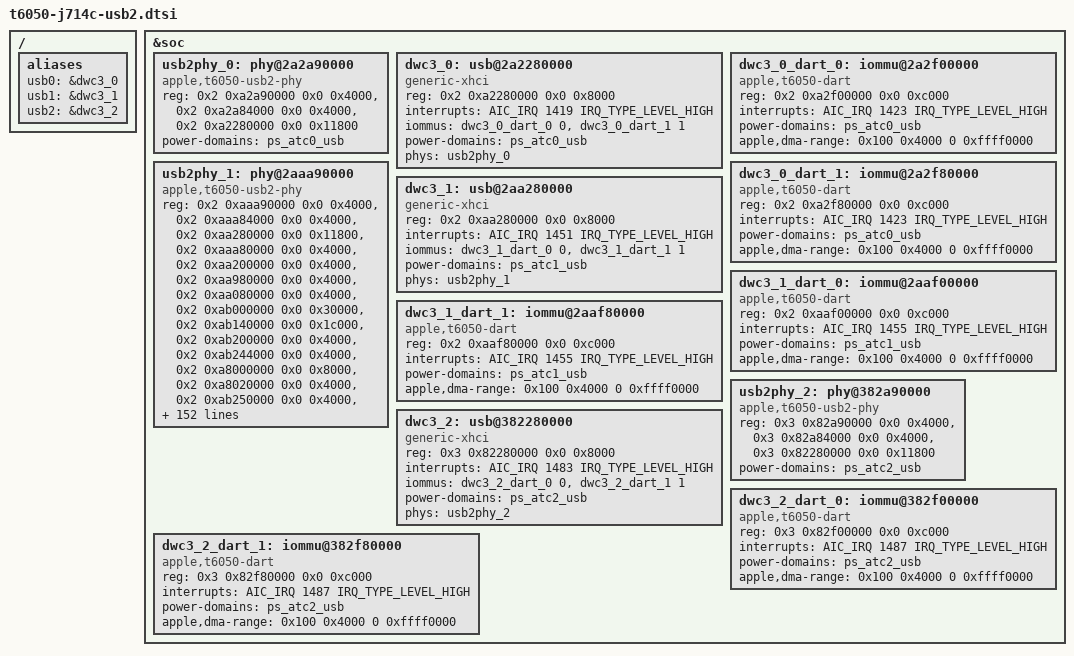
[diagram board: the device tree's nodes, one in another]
// SPDX-License-Identifier: GPL-2.0+ OR MIT
/*
 * USB 2.0 host on USB-C ports 0, 1 and 2 of the MacBook Pro 14" (M5 Max, J714c).
 *
 * The full T6050 Type-C PHY has no Linux driver yet (see t6050-j714c-usb.dtsi).
 * Each port's apple,t6050-usb2-phy puts its usb2phy, pipe handler and dwc3
 * core into USB 2.0 host mode (the loader's usb_t6050_host_prep sequence),
 * and the generic xHCI platform driver drives the xHCI registers after
 * phy_init(). PHY windows: atc-phyN reg 0 (usb2phy) and usb-drdN reg 3
 * (pipe handler). Addresses from
 * the ADT: usb-drd0 0x2a2280000, dart-usb0 0x2a2f00000/0x2a2f80000,
 * usb-drd1 0x2aa280000, dart-usb1 0x2aaf00000/0x2aaf80000,
 * usb-drd2 0x382280000, dart-usb2 0x382f00000/0x382f80000.
 * Port 1 is the proxy cable.
 */

/ {
	aliases {
		usb0 = &dwc3_0;
		usb1 = &dwc3_1;
		usb2 = &dwc3_2;
	};
};

&soc {
	usb2phy_0: phy@2a2a90000 {
		compatible = "apple,t6050-usb2-phy";
		reg = <0x2 0xa2a90000 0x0 0x4000>, <0x2 0xa2a84000 0x0 0x4000>,
		      <0x2 0xa2280000 0x0 0x11800>;
		reg-names = "usb2phy", "pipehandler", "core";
		#phy-cells = <0>;
		power-domains = <&ps_atc0_usb>;
	};

	dwc3_0: usb@2a2280000 {
		compatible = "generic-xhci";
		reg = <0x2 0xa2280000 0x0 0x8000>;
		interrupts = <AIC_IRQ 1419 IRQ_TYPE_LEVEL_HIGH>;
		iommus = <&dwc3_0_dart_0 0>, <&dwc3_0_dart_1 1>;
		power-domains = <&ps_atc0_usb>;
		phys = <&usb2phy_0>;
		phy-names = "usb2-phy";
	};

	dwc3_0_dart_0: iommu@2a2f00000 {
		compatible = "apple,t6050-dart", "apple,t8110-dart";
		reg = <0x2 0xa2f00000 0x0 0xc000>;
		interrupts = <AIC_IRQ 1423 IRQ_TYPE_LEVEL_HIGH>;
		power-domains = <&ps_atc0_usb>;
		#iommu-cells = <1>;
		apple,dma-range = <0x100 0x4000 0 0xffff0000>;
	};

	dwc3_0_dart_1: iommu@2a2f80000 {
		compatible = "apple,t6050-dart", "apple,t8110-dart";
		reg = <0x2 0xa2f80000 0x0 0xc000>;
		interrupts = <AIC_IRQ 1423 IRQ_TYPE_LEVEL_HIGH>;
		power-domains = <&ps_atc0_usb>;
		#iommu-cells = <1>;
		apple,dma-range = <0x100 0x4000 0 0xffff0000>;
	};

	/*
	 * Port 1 also gets SuperSpeed: the Type-C PHY windows (atc-phy1 reg 2,
	 * 38, 39, 40, 41, 42, 43; usb-drd1 reg 1, 5, 6, 8), the PMGR power
	 * states of the CIO domains and of the PHY CPU, and the ADT tunables,
	 * offsets relative to the window of the same name.
	 */
	usb2phy_1: phy@2aaa90000 {
		compatible = "apple,t6050-usb2-phy";
		reg = <0x2 0xaaa90000 0x0 0x4000>, <0x2 0xaaa84000 0x0 0x4000>,
		      <0x2 0xaa280000 0x0 0x11800>, <0x2 0xaaa80000 0x0 0x4000>,
		      <0x2 0xaa200000 0x0 0x4000>, <0x2 0xaa980000 0x0 0x4000>,
		      <0x2 0xaa080000 0x0 0x4000>, <0x2 0xab000000 0x0 0x30000>,
		      <0x2 0xab140000 0x0 0x1c000>, <0x2 0xab200000 0x0 0x4000>,
		      <0x2 0xab244000 0x0 0x4000>, <0x2 0xa8000000 0x0 0x8000>,
		      <0x2 0xa8020000 0x0 0x4000>, <0x2 0xab250000 0x0 0x4000>,
		      <0x2 0x80600000 0x0 0x1000>, <0x2 0x88300000 0x0 0x1000>;
		reg-names = "usb2phy", "pipehandler", "core", "pctl",
			    "drd-cfg", "ausbc-debug", "bulk-fabric", "atc",
			    "atc-mxwrap", "atc-power", "atc-fabric", "atc-axi2af",
			    "atc-axi2af-lioa", "atc-common-cfg", "pmgr", "pmgr-mxwrap";
		#phy-cells = <0>;
		power-domains = <&ps_atc1_usb>;

		apple,tunable-gbl =
			<0xc100 0x8 0x8>,
			<0xc164 0x2 0x0>,
			<0xc104 0x1ef00 0x2f00>,
			<0xc11c 0x100 0x0>,
			<0xc12c 0xa07ff 0x800c8>,
			<0xc200 0x2000100 0x2000100>,
			<0xc604 0x1000 0x0>,
			<0xc628 0xff0000ff 0x6000006>,
			<0xc62c 0xff0000ff 0x8000008>,
			<0xc680 0xffffffff 0x6f000006>,
			<0xc684 0xffffffff 0x60000>;
		apple,tunable-cfg =
			<0x20 0xff 0x1b>;
		apple,tunable-link =
			<0xd010 0xff000000 0xff000000>,
			<0xd020 0x7ff00000 0x4e900000>,
			<0xd024 0x1f8000 0xb8000>,
			<0xd060 0x3ffff 0x600>;
		apple,tunable-ausbc-debug =
			<0xc 0x1f 0x0>;
		apple,tunable-bulk-fabric =
			<0x8 0x8000 0x0>,
			<0x14 0x8000 0x0>,
			<0x20 0x8000 0x0>;
		apple,tunable-pipehandler =
			<0x44 0x4 0x4>;
		apple,tunable-cio =
			<0xcd20 0xff0000 0x1e0000>;
		apple,tunable-atc-common-cfg =
			<0x8 0x1 0x1>;
		apple,tunable-atc-fabric =
			<0x4 0x3f003f 0x200020>,
			<0xc 0xf1 0xa1>,
			<0x10 0x801f 0x4>,
			<0x18 0x3f003f 0x200020>,
			<0x20 0xf1 0xa1>,
			<0x24 0x801f 0x4>,
			<0x2c 0xff00ff 0x960096>,
			<0x34 0xf1 0x71>,
			<0x38 0x801f 0x4>,
			<0x40 0x3f 0x20>,
			<0x48 0x801f 0x4>,
			<0x50 0x7f007f 0x450045>,
			<0x58 0x801f 0x4>,
			<0x60 0x3f 0x20>,
			<0x68 0x801f 0x4>,
			<0x70 0x1 0x1>,
			<0x74 0x801f 0x4>,
			<0x7c 0x7f007f 0x400040>,
			<0x80 0xf1 0x11>,
			<0x84 0x1 0x1>,
			<0x88 0x1 0x1>,
			<0x8c 0x801f 0x4>,
			<0x94 0x3f003f 0x240024>,
			<0x98 0xf1 0x11>,
			<0x9c 0x801f 0x4>,
			<0xa4 0x1ff 0x1e0>,
			<0xa8 0x801f 0x4>,
			<0xb0 0x3f 0x20>,
			<0xb8 0x801f 0x4>,
			<0xc0 0x3f 0x20>,
			<0xc8 0x801f 0x4>,
			<0xd0 0x1f001f 0x100010>,
			<0xd8 0x1 0x1>,
			<0xdc 0x1 0x1>,
			<0xe0 0x801f 0x4>,
			<0xe8 0xf 0x8>,
			<0xec 0x801f 0x4>,
			<0xf4 0xffffffff 0x1010101>,
			<0xf8 0x801f 0x4>,
			<0x100 0x1 0x1>,
			<0x104 0x1 0x1>,
			<0x108 0x801f 0x4>,
			<0x110 0x801f 0x4>,
			<0x118 0x801f 0x4>,
			<0x120 0x1 0x1>,
			<0x124 0x1 0x1>,
			<0x128 0x801f 0x4>,
			<0x130 0xffffffff 0x1010101>,
			<0x134 0x801f 0x4>,
			<0x13c 0x1 0x1>,
			<0x140 0x1 0x1>,
			<0x144 0x801f 0x4>,
			<0x14c 0x1 0x1>,
			<0x150 0x1 0x1>,
			<0x154 0x801f 0x4>,
			<0x15c 0x801f 0x4>,
			<0x164 0xffffffff 0x1010101>,
			<0x168 0xffff 0x101>,
			<0x16c 0x801f 0x4>,
			<0x174 0x1 0x1>,
			<0x178 0x1 0x1>,
			<0x17c 0x801f 0x4>,
			<0x184 0x1 0x1>,
			<0x188 0x1 0x1>,
			<0x18c 0x801f 0x4>;
		apple,tunable-atc-axi2af =
			<0x0 0x800000ff 0x80000023>,
			<0x4 0x80ff00ff 0x80220002>,
			<0x8 0x80ff00ff 0x80220002>,
			<0xc 0x80ff00ff 0x80220006>,
			<0x10 0x80ff00ff 0x80220002>,
			<0x14 0x80ff00ff 0x80200004>,
			<0x18 0x80ff00ff 0x80220002>,
			<0x1c 0x80ff00ff 0x80220002>,
			<0x20 0x80ff00ff 0x80220002>,
			<0x24 0x800000ff 0x8000001a>,
			<0x28 0x800000ff 0x80000046>,
			<0x2c 0x80ff00ff 0x80460004>,
			<0x30 0x80ff00ff 0x80460004>,
			<0x34 0x80ff00ff 0x80420008>,
			<0x38 0x80ff00ff 0x80460004>,
			<0x3c 0x80ff00ff 0x80460004>,
			<0x40 0x800000ff 0x8000001a>,
			<0x44 0x800000ff 0x8000001a>,
			<0x48 0x800000ff 0x8000001d>,
			<0x100 0xff 0xff>,
			<0x104 0x3 0x3>,
			<0x300 0x3 0x1>,
			<0x304 0x3f3f0000 0x4040000>,
			<0x308 0x3ff 0xd>,
			<0x30c 0x700003ff 0xc>,
			<0x310 0x80001f 0x800001>,
			<0x314 0x8080001f 0x80800001>,
			<0x318 0x80001f 0x800001>,
			<0x31c 0x8080001f 0x80800001>,
			<0x320 0x80001f 0x800003>,
			<0x324 0x8080001f 0x80800003>,
			<0x328 0x80001f 0x800003>,
			<0x32c 0x8080001f 0x80800003>,
			<0x330 0x80001f 0x800003>,
			<0x334 0x8080001f 0x80800003>,
			<0x338 0x80001f 0x800003>,
			<0x33c 0x80001f 0x800003>,
			<0x340 0x80001f 0x800003>,
			<0x344 0x80001f 0x800003>,
			<0x348 0x80001f 0x800003>,
			<0x34c 0x80001f 0x800003>,
			<0x350 0x80001f 0x800003>,
			<0x404 0xffff0023 0x1d0021>,
			<0x408 0x3ff 0xd>,
			<0x40c 0x700003ff 0xc>,
			<0x410 0x8000001f 0x80000001>,
			<0x414 0x8000001f 0x80000001>,
			<0x418 0x8000001f 0x80000001>,
			<0x41c 0x8000001f 0x80000001>,
			<0x420 0x8000001f 0x80000003>,
			<0x424 0x8000001f 0x80000003>,
			<0x428 0x8000001f 0x80000003>,
			<0x42c 0x8000001f 0x80000003>,
			<0x430 0x8000001f 0x80000003>,
			<0x434 0x8000001f 0x80000003>,
			<0x438 0x8000001f 0x80000003>,
			<0x43c 0x8000001f 0x80000003>,
			<0x440 0x8000001f 0x80000003>,
			<0x444 0x8000001f 0x80000003>,
			<0x448 0x8000001f 0x80000003>,
			<0x44c 0x8000001f 0x80000003>,
			<0x450 0x8000001f 0x80000003>,
			<0x948 0x7ff07ff 0x280000>,
			<0xa48 0x7ff07ff 0x400040>,
			<0xb48 0x7ff07ff 0xb8010e>,
			<0xc48 0x7ff07ff 0x400020>,
			<0xd48 0x7ff07ff 0x8a008a>,
			<0x1000 0xffffffff 0x7fffffff>,
			<0x1004 0x100 0x100>,
			<0x4008 0x1 0x1>,
			<0x400c 0x1 0x1>,
			<0x4014 0x1 0x1>,
			<0x4018 0x1 0x0>,
			<0x401c 0x1 0x1>,
			<0x108 0xffff0007 0x100001>;
		apple,tunable-atc-pll =
			<0xa04 0x7c 0x50>,
			<0x3224 0xc00 0x800>,
			<0x3230 0x1f 0xf>,
			<0x3240 0x7d8007f 0x4000029>,
			<0x32b0 0xb800000 0x1800000>,
			<0x32e8 0x60001 0x40001>,
			<0x3338 0xf800000 0x7800000>;
		apple,tunable-atc-axi2af-lioa =
			<0x28 0xfc2f 0x0>,
			<0x2c 0x7 0x0>,
			<0x30 0xff 0x0>,
			<0x34 0x3ff 0x0>,
			<0x58 0x30b 0x0>;
		apple,tunable-atc-lanes =
			<0xb698 0x7e00000 0x4400000>,
			<0xb69c 0x7e00000 0x3800000>,
			<0xb6a0 0x7e00000 0x3800000>,
			<0xd094 0x80000 0x80000>,
			<0xd098 0x80000 0x80000>,
			<0xd0a4 0x800000 0x800000>,
			<0xd0a8 0x200000 0x200000>,
			<0x1b698 0x7e00000 0x4400000>,
			<0x1b69c 0x7e00000 0x3800000>,
			<0x1b6a0 0x7e00000 0x3800000>,
			<0x1d094 0x80000 0x80000>,
			<0x1d098 0x80000 0x80000>,
			<0x1d0a4 0x800000 0x800000>,
			<0x1d0a8 0x200000 0x200000>;
	};

	dwc3_1: usb@2aa280000 {
		compatible = "generic-xhci";
		reg = <0x2 0xaa280000 0x0 0x8000>;
		interrupts = <AIC_IRQ 1451 IRQ_TYPE_LEVEL_HIGH>;
		iommus = <&dwc3_1_dart_0 0>, <&dwc3_1_dart_1 1>;
		power-domains = <&ps_atc1_usb>;
		phys = <&usb2phy_1>;
		phy-names = "usb2-phy";
	};

	dwc3_1_dart_0: iommu@2aaf00000 {
		compatible = "apple,t6050-dart", "apple,t8110-dart";
		reg = <0x2 0xaaf00000 0x0 0xc000>;
		interrupts = <AIC_IRQ 1455 IRQ_TYPE_LEVEL_HIGH>;
		power-domains = <&ps_atc1_usb>;
		#iommu-cells = <1>;
		apple,dma-range = <0x100 0x4000 0 0xffff0000>;
	};

	dwc3_1_dart_1: iommu@2aaf80000 {
		compatible = "apple,t6050-dart", "apple,t8110-dart";
		reg = <0x2 0xaaf80000 0x0 0xc000>;
		interrupts = <AIC_IRQ 1455 IRQ_TYPE_LEVEL_HIGH>;
		power-domains = <&ps_atc1_usb>;
		#iommu-cells = <1>;
		apple,dma-range = <0x100 0x4000 0 0xffff0000>;
	};

	usb2phy_2: phy@382a90000 {
		compatible = "apple,t6050-usb2-phy";
		reg = <0x3 0x82a90000 0x0 0x4000>, <0x3 0x82a84000 0x0 0x4000>,
		      <0x3 0x82280000 0x0 0x11800>;
		reg-names = "usb2phy", "pipehandler", "core";
		#phy-cells = <0>;
		power-domains = <&ps_atc2_usb>;
	};

	dwc3_2: usb@382280000 {
		compatible = "generic-xhci";
		reg = <0x3 0x82280000 0x0 0x8000>;
		interrupts = <AIC_IRQ 1483 IRQ_TYPE_LEVEL_HIGH>;
		iommus = <&dwc3_2_dart_0 0>, <&dwc3_2_dart_1 1>;
		power-domains = <&ps_atc2_usb>;
		phys = <&usb2phy_2>;
		phy-names = "usb2-phy";
	};

	dwc3_2_dart_0: iommu@382f00000 {
		compatible = "apple,t6050-dart", "apple,t8110-dart";
		reg = <0x3 0x82f00000 0x0 0xc000>;
		interrupts = <AIC_IRQ 1487 IRQ_TYPE_LEVEL_HIGH>;
		power-domains = <&ps_atc2_usb>;
		#iommu-cells = <1>;
		apple,dma-range = <0x100 0x4000 0 0xffff0000>;
	};

	dwc3_2_dart_1: iommu@382f80000 {
		compatible = "apple,t6050-dart", "apple,t8110-dart";
		reg = <0x3 0x82f80000 0x0 0xc000>;
		interrupts = <AIC_IRQ 1487 IRQ_TYPE_LEVEL_HIGH>;
		power-domains = <&ps_atc2_usb>;
		#iommu-cells = <1>;
		apple,dma-range = <0x100 0x4000 0 0xffff0000>;
	};
};
